# CY8C5888LTI_LP097 register map
File version: 0.1
Registers are 8-bit, read-write, no defined reset value unless marked. A register's access mark holds for its fields unless they carry their own. Offsets are from the block's base; [hi:lo] are bit positions; 'fields as' and 'values as' point back to an identical list.

## S4_Timer
Base 0x00000000
0x4000640A S4_Timer_COUNTER 16-bit — UDB.A0 - Current Down Counter Value
0x4000642A S4_Timer_PERIOD 16-bit — UDB.D0 - Assigned Period
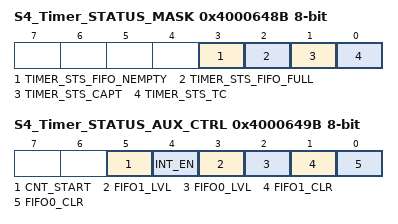
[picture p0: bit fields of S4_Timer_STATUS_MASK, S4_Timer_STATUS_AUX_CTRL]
0x4000648B S4_Timer_STATUS_MASK — UDB Status bits Interrupt Mask Enable Register
  [3] TIMER_STS_FIFO_NEMPTY ro — FIFO Empty status
  [2] TIMER_STS_FIFO_FULL ro — FIFO Full Status
  [1] TIMER_STS_CAPT ro — Enables the Interrupt on Capture
  [0] TIMER_STS_TC ro — Enables the Interrupt on TC
0x4000649B S4_Timer_STATUS_AUX_CTRL — UDB Auxilliary Control Register
  [5] CNT_START — FIFO0 clear
    0=E_CNT_START0 (Disable counter); 1=E_CNT_START1 (Enable counter)
  [4] INT_EN
    0=E_INT_EN0 (Interrupt disabled); 1=E_INT_EN1 (Interrupt enabled)
  [3] FIFO1_LVL — FIFO level
    0=E_FIFO_LVL_0 (FIFO LVL: input mode: FIFO not full; output mode: FIFO not empty); 1=E_FIFO_LVL_1 (FIFO LVL: input mode: FIFO at least 1/2 empty; output mode: FIFO at least 1/2 full)
  [2] FIFO0_LVL — FIFO level
    values as FIFO1_LVL
  [1] FIFO1_CLR — FIFO1 clear
    0=E_FIFO_CLR_0 (Normal FIFO operation); 1=E_FIFO_CLR_1 (Clear FIFO state)
  [0] FIFO0_CLR — FIFO0 clear
    values as FIFO1_CLR

## RobotArm_Servo
Base 0x00000000
0x40006424 RobotArm_Servo_COMPARE_1 16-bit — UDB.D0 - Assigned Compare1 Value
0x40006434 RobotArm_Servo_COMPARE_2 16-bit — UDB.D1 - Assigned Compare2 Value
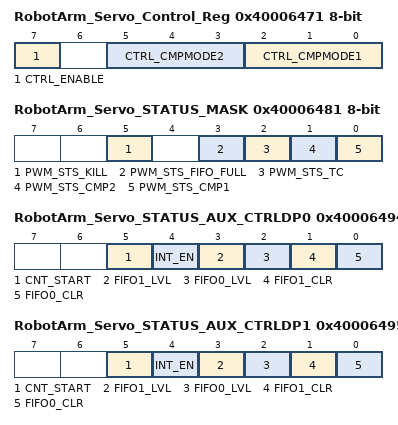
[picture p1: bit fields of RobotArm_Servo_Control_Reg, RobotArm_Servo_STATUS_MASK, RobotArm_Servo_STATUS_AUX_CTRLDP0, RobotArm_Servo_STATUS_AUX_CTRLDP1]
0x40006471 RobotArm_Servo_Control_Reg — UDB Control Register - Assigned Control Register Value
  [7] CTRL_ENABLE — Enable the PWM
  [5:3] CTRL_CMPMODE2 — Compare mode 2
  [2:0] CTRL_CMPMODE1 — Compare mode 1
0x40006481 RobotArm_Servo_STATUS_MASK — UDB Status bits Interrupt Mask Enable Register
  [5] PWM_STS_KILL ro — Enables the Interrupt on Kill
  [3] PWM_STS_FIFO_FULL ro — FIFO Full Status Mask
  [2] PWM_STS_TC ro — Enables the Interrupt on Terminal Count
  [1] PWM_STS_CMP2 ro — Enables the Interrupt on Compare 2
  [0] PWM_STS_CMP1 ro — Enables the Interrupt on Compare 1
0x40006494 RobotArm_Servo_STATUS_AUX_CTRLDP0 — UDB Auxilliary Control Register
  [5] CNT_START — FIFO0 clear
    0=E_CNT_START0 (Disable counter); 1=E_CNT_START1 (Enable counter)
  [4] INT_EN
    0=E_INT_EN0 (Interrupt disabled); 1=E_INT_EN1 (Interrupt enabled)
  [3] FIFO1_LVL — FIFO level
    0=E_FIFO_LVL_0 (FIFO LVL: input mode: FIFO not full; output mode: FIFO not empty); 1=E_FIFO_LVL_1 (FIFO LVL: input mode: FIFO at least 1/2 empty; output mode: FIFO at least 1/2 full)
  [2] FIFO0_LVL — FIFO level
    values as FIFO1_LVL
  [1] FIFO1_CLR — FIFO1 clear
    0=E_FIFO_CLR_0 (Normal FIFO operation); 1=E_FIFO_CLR_1 (Clear FIFO state)
  [0] FIFO0_CLR — FIFO0 clear
    values as FIFO1_CLR
0x40006495 RobotArm_Servo_STATUS_AUX_CTRLDP1 — UDB Auxilliary Control Register
  fields as RobotArm_Servo_STATUS_AUX_CTRLDP0

## UART
Base 0x00000000
0x40006427 RX_UART_RX_ADDRESS1 — RX Address1 Register
0x40006437 RX_UART_RX_ADDRESS2 — RX Address2 Register
0x40006440 TX_UART_TX_DATA — TX Data Register
0x40006447 RX_UART_RX_DATA — RX Data Register
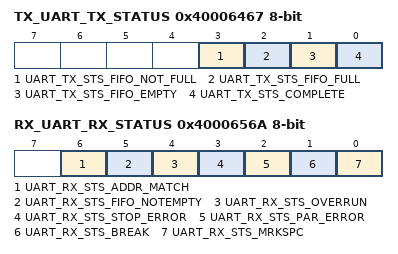
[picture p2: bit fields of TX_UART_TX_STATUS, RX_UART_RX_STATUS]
0x40006467 TX_UART_TX_STATUS — TX status register
  [3] UART_TX_STS_FIFO_NOT_FULL ro, [2] UART_TX_STS_FIFO_FULL ro, [1] UART_TX_STS_FIFO_EMPTY ro, [0] UART_TX_STS_COMPLETE ro
0x4000656A RX_UART_RX_STATUS — RX status register
  [6] UART_RX_STS_ADDR_MATCH ro, [5] UART_RX_STS_FIFO_NOTEMPTY ro, [4] UART_RX_STS_OVERRUN ro, [3] UART_RX_STS_STOP_ERROR ro, [2] UART_RX_STS_PAR_ERROR ro, [1] UART_RX_STS_BREAK ro, [0] UART_RX_STS_MRKSPC ro

## QuadDec_L
Base 0x00000000
0x4000640E QuadDec_L_Cnt16_COUNTER 16-bit — Counter value
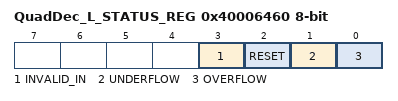
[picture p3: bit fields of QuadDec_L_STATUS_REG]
0x40006460 QuadDec_L_STATUS_REG — Quadrature Decoder Status Register
  [3] INVALID_IN ro — Invalid state transition on the A and B inputs
  [2] RESET ro — Counter Reset due index
  [1] UNDERFLOW ro — Counter underflow
  [0] OVERFLOW ro — Counter overflow
